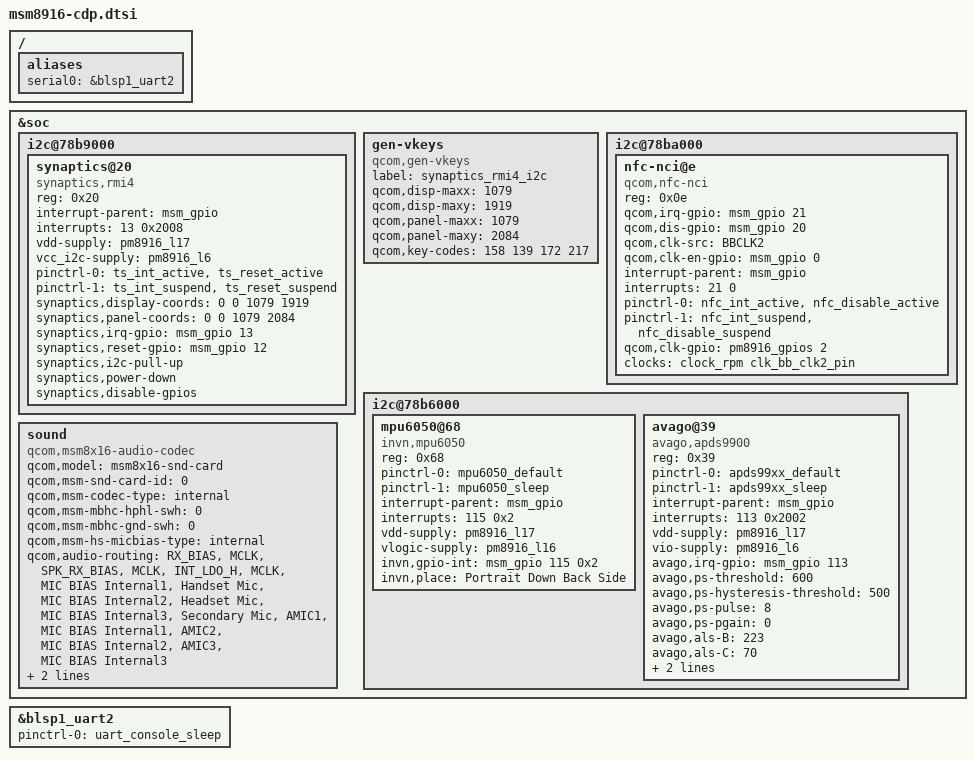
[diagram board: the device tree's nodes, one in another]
/* Copyright (c) 2014, The Linux Foundation. All rights reserved.
 *
 * This program is free software; you can redistribute it and/or modify
 * it under the terms of the GNU General Public License version 2 and
 * only version 2 as published by the Free Software Foundation.
 *
 * This program is distributed in the hope that it will be useful,
 * but WITHOUT ANY WARRANTY; without even the implied warranty of
 * MERCHANTABILITY or FITNESS FOR A PARTICULAR PURPOSE.  See the
 * GNU General Public License for more details.
 */

#include "msm8916.dtsi"
#include "msm8916-pinctrl.dtsi"

/ {
	aliases {
		serial0 = &blsp1_uart2;
	};
};

&soc {
	i2c@78b9000 { /* BLSP1 QUP5 */
		synaptics@20 {
			compatible = "synaptics,rmi4";
			reg = <0x20>;
			interrupt-parent = <&msm_gpio>;
			interrupts = <13 0x2008>;
			vdd-supply = <&pm8916_l17>;
			vcc_i2c-supply = <&pm8916_l6>;
			/* pins used by touchscreen */
			pinctrl-names = "pmx_ts_active","pmx_ts_suspend";
			pinctrl-0 = <&ts_int_active &ts_reset_active>;
			pinctrl-1 = <&ts_int_suspend &ts_reset_suspend>;
			synaptics,display-coords = <0 0 1079 1919>;
			synaptics,panel-coords = <0 0 1079 2084>;
			synaptics,irq-gpio = <&msm_gpio 13 0x2008>;
			synaptics,reset-gpio = <&msm_gpio 12 0x0>;
			synaptics,i2c-pull-up;
			synaptics,power-down;
			synaptics,disable-gpios;
		};
	};

	gen-vkeys {
		compatible = "qcom,gen-vkeys";
		label = "synaptics_rmi4_i2c";
		qcom,disp-maxx = <1079>;
		qcom,disp-maxy = <1919>;
		qcom,panel-maxx = <1079>;
		qcom,panel-maxy = <2084>;
		qcom,key-codes = <158 139 172 217>;
	};

	i2c@78ba000 { /* BLSP1 QUP6 */
		nfc-nci@e {
			compatible = "qcom,nfc-nci";
			reg = <0x0e>;
			qcom,irq-gpio = <&msm_gpio 21 0x00>;
			qcom,dis-gpio = <&msm_gpio 20 0x00>;
			qcom,clk-src = "BBCLK2";
			qcom,clk-en-gpio = <&msm_gpio 0 0x00>;
			interrupt-parent = <&msm_gpio>;
			interrupts = <21 0>;
			pinctrl-names = "nfc_active","nfc_suspend";
			pinctrl-0 = <&nfc_int_active &nfc_disable_active>;
			pinctrl-1 = <&nfc_int_suspend &nfc_disable_suspend>;
			qcom,clk-gpio = <&pm8916_gpios 2 0>;
			clocks = <&clock_rpm clk_bb_clk2_pin>;
			clock-names = "ref_clk";
		};
	};

	i2c@78b6000 { /* BLSP1 QUP2 */
		mpu6050@68 { /* Gyroscope and accelerometer sensor combo */
			compatible = "invn,mpu6050";
			reg = <0x68>;
			pinctrl-names = "mpu_default","mpu_sleep";
			pinctrl-0 = <&mpu6050_default>;
			pinctrl-1 = <&mpu6050_sleep>;
			interrupt-parent = <&msm_gpio>;
			interrupts = <115 0x2>;
			vdd-supply = <&pm8916_l17>;
			vlogic-supply = <&pm8916_l16>;
			invn,gpio-int = <&msm_gpio 115 0x2>;
			invn,place = "Portrait Down Back Side";
		};

		avago@39 { /* Ambient light and proximity sensor */
			compatible = "avago,apds9900";
			reg = <0x39>;
			pinctrl-names = "default","sleep";
			pinctrl-0 = <&apds99xx_default>;
			pinctrl-1 = <&apds99xx_sleep>;
			interrupt-parent = <&msm_gpio>;
			interrupts = <113 0x2002>;
			vdd-supply = <&pm8916_l17>;
			vio-supply = <&pm8916_l6>;
			avago,irq-gpio = <&msm_gpio 113 0x2002>;
			avago,ps-threshold = <600>;
			avago,ps-hysteresis-threshold = <500>;
			avago,ps-pulse = <8>;
			avago,ps-pgain = <0>;
			avago,als-B = <223>;
			avago,als-C = <70>;
			avago,als-D = <142>;
			avago,ga-value = <48>;
		};
	};

	sound {
		compatible = "qcom,msm8x16-audio-codec";
		qcom,model = "msm8x16-snd-card";
		qcom,msm-snd-card-id = <0>;
		qcom,msm-codec-type = "internal";
		qcom,msm-mbhc-hphl-swh = <0>;
		qcom,msm-mbhc-gnd-swh = <0>;
		qcom,msm-hs-micbias-type = "internal";
		qcom,audio-routing =
			"RX_BIAS", "MCLK",
			"SPK_RX_BIAS", "MCLK",
			"INT_LDO_H", "MCLK",
			"MIC BIAS Internal1", "Handset Mic",
			"MIC BIAS Internal2", "Headset Mic",
			"MIC BIAS Internal3", "Secondary Mic",
			"AMIC1", "MIC BIAS Internal1",
			"AMIC2", "MIC BIAS Internal2",
			"AMIC3", "MIC BIAS Internal3";
		pinctrl-names = "cdc_pdm_lines_act",
				"cdc_pdm_lines_sus";
		pinctrl-0 = <&cdc_pdm_lines_act>;
		pinctrl-1 = <&cdc_pdm_lines_sus>;
	};
};

&blsp1_uart2 {
	status = "ok";
	pinctrl-names = "default";
	pinctrl-0 = <&uart_console_sleep>;
};
